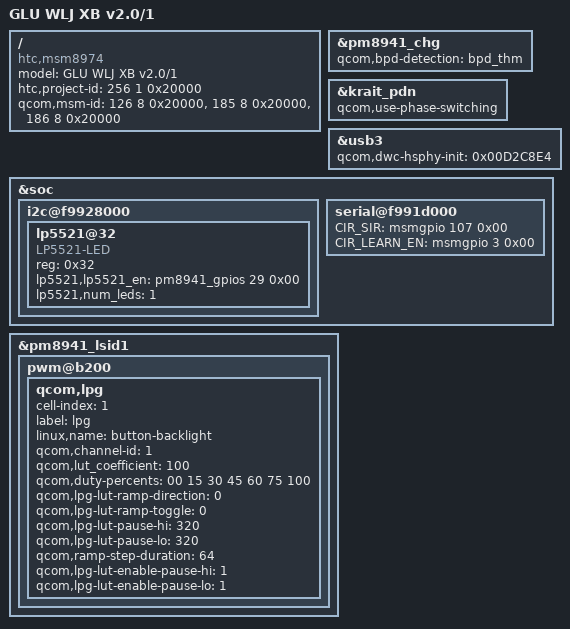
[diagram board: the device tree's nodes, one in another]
/* Copyright (c) 2013, The Linux Foundation. All rights reserved.
 *
 * This program is free software; you can redistribute it and/or modify
 * it under the terms of the GNU General Public License version 2 and
 * only version 2 as published by the Free Software Foundation.
 *
 * This program is distributed in the hope that it will be useful,
 * but WITHOUT ANY WARRANTY; without even the implied warranty of
 * MERCHANTABILITY or FITNESS FOR A PARTICULAR PURPOSE.  See the
 * GNU General Public License for more details.
 */

/dts-v1/;

/include/ "msm8974-v2.0-1.dtsi"
/include/ "msm8974-glu-regulator.dtsi"
/include/ "msm8974-glu-common.dtsi"
/include/ "msm8974-gluwlj-pmicgpio.dtsi"

/ {
	model = "GLU WLJ XB v2.0/1";
	compatible = "htc,msm8974", "htc,gluwlj", "qcom,msm8974-mtp", "qcom,msm8974", "qcom,mtp";
	htc,project-id = <256 1 0x20000>;  /* <pid hw-version soc-rev> */
	qcom,msm-id = <126 8 0x20000>,
		      <185 8 0x20000>,
		      <186 8 0x20000>;
};

&pm8941_chg {
	qcom,bpd-detection = "bpd_thm";
};

&krait_pdn {
	qcom,use-phase-switching;
};

&usb3 {
       qcom,dwc-hsphy-init = <0x00D2C8E4>;
};

&soc {
	i2c@f9928000 {
		lp5521@32 {
			compatible = "LP5521-LED";
			reg = <0x32>;
			lp5521,lp5521_en = <&pm8941_gpios 29 0x00>;
			lp5521,num_leds = <1>;
		};
	};
	serial@f991d000 {
		CIR_SIR = <&msmgpio 107 0x00>;
		CIR_LEARN_EN = <&msmgpio 3 0x00>;
	};
};

&pm8941_lsid1 {
	pwm@b200 {
		qcom,lpg {
			cell-index = <1>;
			label = "lpg";
			linux,name = "button-backlight";
			qcom,channel-id = <1>;
			qcom,lut_coefficient = <100>;
			qcom,duty-percents = <00 15 30 45 60 75 100>; //Use percents in decimal, not in hex like in LED duty-pcts array
			qcom,lpg-lut-ramp-direction = <0>;
			qcom,lpg-lut-ramp-toggle = <0>;
			qcom,lpg-lut-pause-hi = <320>;
			qcom,lpg-lut-pause-lo = <320>;
			qcom,ramp-step-duration = <64>;
			qcom,lpg-lut-enable-pause-hi = <1>;
			qcom,lpg-lut-enable-pause-lo = <1>;
		};
	};
};
